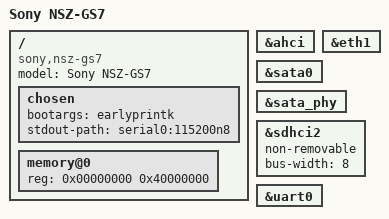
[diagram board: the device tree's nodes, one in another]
/dts-v1/;
#include "berlin2.dtsi"
/ {
	model = "Sony NSZ-GS7";
	compatible = "sony,nsz-gs7", "marvell,berlin2", "marvell,berlin";
	chosen {
		bootargs = "earlyprintk";
		stdout-path = "serial0:115200n8";
	};
	memory@0 {
		device_type = "memory";
		reg = <0x00000000 0x40000000>;  
	};
};
&ahci { status = "okay"; };
&eth1 { status = "okay"; };
&sata0 { status = "okay"; };
&sata_phy { status = "okay"; };
&sdhci2 {
	non-removable;
	bus-width = <8>;
	status = "okay";
};
&uart0 { status = "okay"; };
